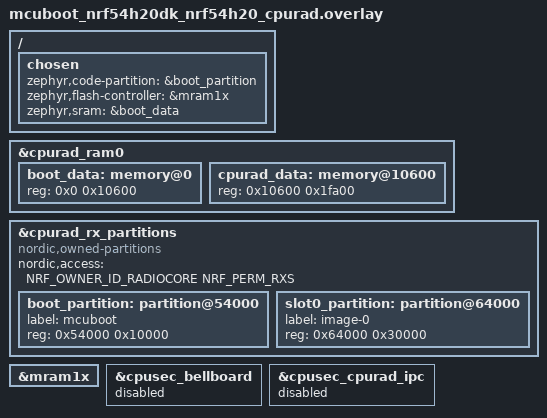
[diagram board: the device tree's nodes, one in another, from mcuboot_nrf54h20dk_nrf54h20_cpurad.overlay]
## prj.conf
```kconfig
# nothing here
CONFIG_XIP=n
CONFIG_BOOTLOADER_MCUBOOT=y
CONFIG_MCUBOOT_SIGNATURE_KEY_FILE="./bootloader/mcuboot/root-rsa-2048.pem"
CONFIG_MCUBOOT_BOOTLOADER_MODE_SINGLE_APP=y
CONFIG_CLOCK_CONTROL=y
CONFIG_NRF_SYS_EVENT=y
CONFIG_ZERO_LATENCY_IRQS=y
```

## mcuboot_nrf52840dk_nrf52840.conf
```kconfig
CONFIG_ARM_MPU=n
CONFIG_SINGLE_APPLICATION_SLOT=y
CONFIG_SINGLE_APPLICATION_SLOT_RAM_LOAD=y
CONFIG_BOOT_IMAGE_EXECUTABLE_RAM_START=0x20010000
CONFIG_BOOT_IMAGE_EXECUTABLE_RAM_SIZE=196608
```

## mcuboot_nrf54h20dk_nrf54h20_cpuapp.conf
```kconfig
CONFIG_ARM_MPU=n
CONFIG_SINGLE_APPLICATION_SLOT=y
CONFIG_SINGLE_APPLICATION_SLOT_RAM_LOAD=y
# Vector table alignment must match 256-word boundary after header of 512 bits
CONFIG_BOOT_IMAGE_EXECUTABLE_RAM_START=0x2f022600
CONFIG_BOOT_IMAGE_EXECUTABLE_RAM_SIZE=195072
CONFIG_FLASH=y
CONFIG_SPI_NOR=n
CONFIG_BOOT_WATCHDOG_FEED=n
CONFIG_NRFS=n
CONFIG_SOC_NRF54H20_GPD=n

CONFIG_SERIAL=n
CONFIG_PRINTK=n
CONFIG_GPIO=n
CONFIG_LOG=n
CONFIG_LOG_MODE_MINIMAL=y
CONFIG_CONSOLE=n
CONFIG_UART_CONSOLE=n
```

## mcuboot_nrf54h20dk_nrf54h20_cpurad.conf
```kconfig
CONFIG_ARM_MPU=n
CONFIG_SINGLE_APPLICATION_SLOT=y
CONFIG_SINGLE_APPLICATION_SLOT_RAM_LOAD=y
# Vector table alignment must match 256-word boundary after header of 512 bits
CONFIG_BOOT_IMAGE_EXECUTABLE_RAM_START=0x23010600
CONFIG_BOOT_IMAGE_EXECUTABLE_RAM_SIZE=129536
CONFIG_FLASH=y
CONFIG_SPI_NOR=n
CONFIG_BOOT_WATCHDOG_FEED=n
CONFIG_NRFS=n
CONFIG_SOC_NRF54H20_GPD=n

CONFIG_SERIAL=n
CONFIG_PRINTK=n
CONFIG_GPIO=n
CONFIG_LOG=n
CONFIG_LOG_MODE_MINIMAL=y
CONFIG_CONSOLE=n
CONFIG_UART_CONSOLE=n
```

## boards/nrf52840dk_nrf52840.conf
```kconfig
CONFIG_MCUBOOT_EXTRA_IMGTOOL_ARGS="--load-addr 0x20010000"
CONFIG_SRAM_BASE_ADDRESS=0x20010000
CONFIG_ARM_MPU=n
```

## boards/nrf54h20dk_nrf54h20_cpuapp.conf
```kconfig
CONFIG_MCUBOOT_EXTRA_IMGTOOL_ARGS="--load-addr 0x2f022600"
CONFIG_SRAM_BASE_ADDRESS=0x2f022600
CONFIG_BOOT_DELAY=8000
CONFIG_ARM_MPU=n

CONFIG_PM=y
CONFIG_PM_S2RAM=y
CONFIG_PM_S2RAM_CUSTOM_MARKING=y
CONFIG_POWEROFF=y

CONFIG_BOOT_BANNER=n

# Enable for debugging purposes only
CONFIG_SERIAL=n
CONFIG_PRINTK=n
CONFIG_GPIO=n
CONFIG_LOG=n
CONFIG_CONSOLE=n
CONFIG_UART_CONSOLE=n

CONFIG_BOOT_DELAY=4000
```

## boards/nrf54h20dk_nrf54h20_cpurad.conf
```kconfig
CONFIG_MCUBOOT_EXTRA_IMGTOOL_ARGS="--load-addr 0x23010600"
CONFIG_SRAM_BASE_ADDRESS=0x23010600
CONFIG_BOOT_DELAY=4000
CONFIG_ARM_MPU=n

CONFIG_PM=y
CONFIG_POWEROFF=y
CONFIG_CONSOLE=n
CONFIG_UART_CONSOLE=n
CONFIG_SERIAL=n
CONFIG_GPIO=n
CONFIG_BOOT_BANNER=n
```

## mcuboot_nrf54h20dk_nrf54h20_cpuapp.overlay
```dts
&cpuapp_rx_partitions{
	#address-cells = <1>;
	#size-cells = <1>;

	/delete-node/ partition@94000;

	boot_partition: partition@94000 {
		label = "mcuboot";
		reg = <0x94000 DT_SIZE_K(64)>;
	};

	slot0_partition: partition@a4000 {
		label = "image-0";
		reg = <0xa4000 DT_SIZE_K(256)>;
	};
};

&cpuapp_ram0x_region {
	nordic,access = <NRF_OWNER_ID_APPLICATION NRF_PERM_RWXS>;

	/delete-node/ memory@1000;

	boot_data: memory@1000 {
		reg = <0x1000 DT_SIZE_K(64)>;
	};

	cpuapp_data: memory@11000 {
		reg = <0x11000 DT_SIZE_K(192)>;
	};
};

/{
	chosen {
		zephyr,code-partition = &boot_partition;
		zephyr,flash-controller = &mram1x;
		zephyr,sram = &boot_data;
	};
};

&mram1x {
	status = "okay";
};
```

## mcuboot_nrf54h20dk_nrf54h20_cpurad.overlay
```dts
/* 23000000 */
&cpurad_ram0 {
	boot_data: memory@0 {
		reg = <0x0 0x10600>;
	};

	cpurad_data: memory@10600 {
		reg = <0x10600 0x1fa00>;
	};
};

/* 0xe000000 */
&cpurad_rx_partitions {
	compatible = "nordic,owned-partitions", "fixed-partitions";
	status = "okay";
	nordic,access = <NRF_OWNER_ID_RADIOCORE NRF_PERM_RXS>;
	#address-cells = <1>;
	#size-cells = <1>;

	/delete-node/ partition@54000;

	boot_partition: partition@54000 {
		label = "mcuboot";
		reg = <0x54000 0x10000>;
	};

	slot0_partition: partition@64000 {
		label = "image-0";
		reg = <0x64000 0x30000>;
	};
};

/{
	chosen {
		zephyr,code-partition = &boot_partition;
		zephyr,flash-controller = &mram1x;
		zephyr,sram = &boot_data;
	};
};

&mram1x {
	status = "okay";
};

&cpusec_bellboard {
	status = "disabled";
};

&cpusec_cpurad_ipc {
	status = "disabled";
};
```

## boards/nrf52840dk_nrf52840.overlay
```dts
&sram0 {
	partitions {
		compatible = "fixed-partitions";
		#address-cells = < 0x1 >;
		#size-cells = < 0x1 >;
		sram0_boot_sram_part: partition@0 {
			label = "boot-sram";
			reg = < 0x0 0x10000 >;
		};
		sram0_app_code_part: partition@10000 {
			label = "app-code";
			reg = < 0x10000 0x20000 >;
		};
		sram0_app_sram_part: partition@30000 {
			label = "app-sram";
			reg = < 0x30000 0x10000 >;
		};
	};
};

/{
	chosen {
		zephyr,code-partition = &sram0_app_code_part;
		zephyr,sram = &sram0_app_sram_part;
	};
};
```

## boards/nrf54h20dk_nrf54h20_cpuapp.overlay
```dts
&cpuapp_rx_partitions {
	#address-cells = <1>;
	#size-cells = <1>;

	/delete-node/ partition@94000;

	boot_partition: partition@94000 {
		label = "mcuboot";
		reg = <0x94000 DT_SIZE_K(64)>;
	};

	slot0_partition: partition@a4000 {
		label = "image-0";
		reg = <0xa4000 DT_SIZE_K(256)>;
	};
};

&cpuapp_ram0x_region {
	/delete-node/ memory@1000;

	boot_data: memory@1000 {
		reg = <0x1000 0x10600>;
	};

	cpuapp_data: memory@11600 {
		reg = <0x11600 0x2fa00>;
	};
};

/{
	chosen {
		zephyr,code-partition = &slot0_partition;
		zephyr,flash-controller = &mram1x;
		zephyr,sram = &cpuapp_data;
	};
};
```

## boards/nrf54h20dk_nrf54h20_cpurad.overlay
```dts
/* 23000000 */
&cpurad_ram0 {
	boot_data: memory@0 {
		reg = <0x0 0x10600>;
	};

	cpurad_data: memory@10600 {
		reg = <0x10600 0x1fa00>;
	};
};

/* 0xe000000 */
&cpurad_rx_partitions {
	compatible = "nordic,owned-partitions", "fixed-partitions";
	status = "okay";
	nordic,access = <NRF_OWNER_ID_RADIOCORE NRF_PERM_RXS>;
	#address-cells = <1>;
	#size-cells = <1>;

	/delete-node/ partition@54000;

	boot_partition: partition@54000 {
		label = "mcuboot";
		reg = <0x54000 0x10000>;
	};

	slot0_partition: partition@64000 {
		label = "image-0";
		reg = <0x64000 0x30000>;
	};
};

/{
	chosen {
		zephyr,code-partition = &slot0_partition;
		zephyr,sram = &cpurad_data;
	};
};

&cpusec_bellboard {
	status = "disabled";
};

&cpusec_cpurad_ipc {
	status = "disabled";
};
```

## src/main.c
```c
/*
 * Copyright (c) 2012-2014 Wind River Systems, Inc.
 *
 * SPDX-License-Identifier: Apache-2.0
 */

#include <zephyr/kernel.h>
#include <zephyr/drivers/clock_control/nrf_clock_control.h>
#include <nrf_sys_event.h>
#include <soc.h>

int main(void)
{
	/* Workaround for HM-24529
	* Make sure HSFLL is on whenever RADIO does DMA
	*/
	NRF_LRCCONF000->CLKCTRL[0].ALWAYSRUN = 1;
	NRF_LRCCONF000->TASKS_REQCLKSRC[0]   = 1;

	while (1) {
		k_msleep(200);
		nrf_clock_control_hfxo_request();
		k_usleep(1300);
		//nrf_sys_event_request_global_constlat();
		k_usleep(100);
		k_busy_wait(300);
		//nrf_sys_event_release_global_constlat();
		nrf_clock_control_hfxo_release();
	}

	return 0;
}
```
